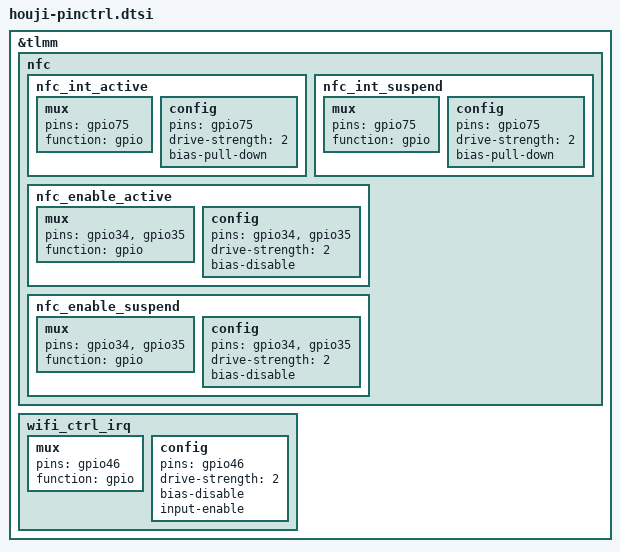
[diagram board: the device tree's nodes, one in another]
/*for houji pinctrl */
&tlmm {
	nfc {
		nfc_int_active: nfc_int_active {
			/* active state */
			mux {
				/* NFC Read Interrupt */
				pins = "gpio75";
				function = "gpio";
			};

			config {
				pins = "gpio75";
				drive-strength = <2>; /* 2 MA */
				bias-pull-down;
			};
		};

		nfc_int_suspend: nfc_int_suspend {
			/* sleep state */
			mux {
				/* NFC Read Interrupt */
				pins = "gpio75";
				function = "gpio";
			};

			config {
				pins = "gpio75";
				drive-strength = <2>; /* 2 MA */
				bias-pull-down;
			};
		};

		nfc_enable_active: nfc_enable_active {
			mux {
				/* Enable, and Clock request gpios */
				pins = "gpio34", "gpio35";
				function = "gpio";
			};

			config {
				pins = "gpio34", "gpio35";
				drive-strength = <2>; /* 2 MA */
				bias-disable;
			};
		};

		nfc_enable_suspend: nfc_enable_suspend {
			mux {
				pins = "gpio34", "gpio35";
				function = "gpio";
			};

			config {
				pins = "gpio34", "gpio35";
				drive-strength = <2>; /* 2 MA */
				bias-disable;
			};
		};
	}; //nfc

	wifi_ctrl_irq: wifi_ctrl_irq {
		mux {
			pins = "gpio46";
			function = "gpio";
		};
		config {
			pins = "gpio46";
			drive-strength = <2>;   /* 2 mA */
			bias-disable;
			input-enable;
		};
	}; //wifi
}; //tlmm
